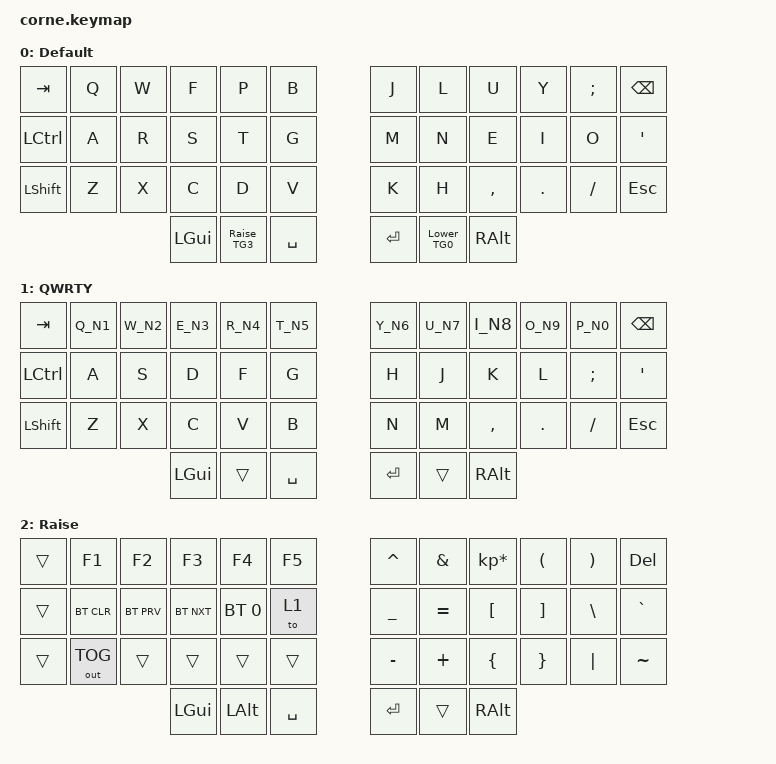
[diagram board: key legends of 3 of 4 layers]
/*
 * Copyright (c) 2020 The ZMK Contributors
 *
 * SPDX-License-Identifier: MIT
 */

#include <behaviors.dtsi>
#include <dt-bindings/zmk/bt.h>
#include <dt-bindings/zmk/keys.h>
#include <dt-bindings/zmk/outputs.h>

/ {
    behaviors {
        Lower_TG0: Lower_TG0 {
            compatible = "zmk,behavior-tap-dance";
            label = "LOWER_TG0";
            #binding-cells = <0>;
            bindings = <&mo 3>, <&tog 0>;

            tapping-term-ms = <200>;
        };

        Raise_TG3: Raise_TG3 {
            compatible = "zmk,behavior-tap-dance";
            label = "RAISE_TG3";
            #binding-cells = <0>;
            bindings = <&mo 2>, <&tog 1>;

            tapping-term-ms = <200>;
        };

        Q_N1: Q_N1 {
            compatible = "zmk,behavior-tap-dance";
            label = "Q_N1";
            #binding-cells = <0>;
            bindings = <&kp Q>, <&kp NUMBER_1>;

            tapping-term-ms = <200>;
        };

        W_N2: W_N2 {
            compatible = "zmk,behavior-tap-dance";
            label = "W_N2";
            #binding-cells = <0>;
            bindings = <&kp W>, <&kp NUMBER_2>;

            tapping-term-ms = <200>;
        };

        E_N3-8:

        E_N3-8 {
            compatible = "zmk,behavior-tap-dance";
            label = "E_N3-8";
            #binding-cells = <0>;
            bindings = <&kp E>, <&kp NUMBER_3>, <&kp N8>;

            tapping-term-ms = <175>;
        };

        F_N3: F_N3 {
            compatible = "zmk,behavior-tap-dance";
            label = "F_N3";
            #binding-cells = <0>;
            bindings = <&kp F>, <&kp NUMBER_3>;

            tapping-term-ms = <200>;
        };

        R_N4-9:

        R_N4-9 {
            compatible = "zmk,behavior-tap-dance";
            label = "R_N4-9";
            #binding-cells = <0>;
            bindings = <&kp R>, <&kp NUMBER_4>, <&kp N9>;

            tapping-term-ms = <175>;
        };

        P_N4: P_N4 {
            compatible = "zmk,behavior-tap-dance";
            label = "P_N4";
            #binding-cells = <0>;
            bindings = <&kp P>, <&kp NUMBER_4>;

            tapping-term-ms = <200>;
        };

        T_N5-0:

        T_N5-0 {
            compatible = "zmk,behavior-tap-dance";
            label = "T_N5-0";
            #binding-cells = <0>;
            bindings = <&kp T>, <&kp N5>, <&kp N0>;

            tapping-term-ms = <175>;
        };

        B_N5: B_N5 {
            compatible = "zmk,behavior-tap-dance";
            label = "B_N5";
            #binding-cells = <0>;
            bindings = <&kp B>, <&kp N5>;

            tapping-term-ms = <200>;
        };

        Y_N6: Y_N6 {
            compatible = "zmk,behavior-tap-dance";
            label = "Y_N6";
            #binding-cells = <0>;
            bindings = <&kp Y>, <&kp NUMBER_6>;

            tapping-term-ms = <200>;
        };

        J_N6: J_N6 {
            compatible = "zmk,behavior-tap-dance";
            label = "J_N6";
            #binding-cells = <0>;
            bindings = <&kp J>, <&kp NUMBER_6>;

            tapping-term-ms = <200>;
        };

        U_N7: U_N7 {
            compatible = "zmk,behavior-tap-dance";
            label = "U_N7";
            #binding-cells = <0>;
            bindings = <&kp U>, <&kp N7>;

            tapping-term-ms = <200>;
        };

        L_N7: L_N7 {
            compatible = "zmk,behavior-tap-dance";
            label = "L_N7";
            #binding-cells = <0>;
            bindings = <&kp L>, <&kp N7>;

            tapping-term-ms = <200>;
        };

        I_N8: I_N8 {
            compatible = "zmk,behavior-tap-dance";
            label = "I_N8";
            #binding-cells = <0>;
            bindings = <&kp I>, <&kp N8>;

            tapping-term-ms = <200>;
        };

        U_N8: U_N8 {
            compatible = "zmk,behavior-tap-dance";
            label = "U_N8";
            #binding-cells = <0>;
            bindings = <&kp U>, <&kp N8>;

            tapping-term-ms = <200>;
        };

        O_N9: O_N9 {
            compatible = "zmk,behavior-tap-dance";
            label = "O_N9";
            #binding-cells = <0>;
            bindings = <&kp O>, <&kp N9>;

            tapping-term-ms = <200>;
        };

        Y_N9: Y_N9 {
            compatible = "zmk,behavior-tap-dance";
            label = "Y_N9";
            #binding-cells = <0>;
            bindings = <&kp Y>, <&kp N9>;

            tapping-term-ms = <200>;
        };

        W_N2-7:

        W_N2-7 {
            compatible = "zmk,behavior-tap-dance";
            label = "W_N2-7";
            #binding-cells = <0>;
            bindings = <&kp W>, <&kp NUMBER_2>, <&kp N7>;

            tapping-term-ms = <175>;
        };

        CAP_CTRL: CAP_CTRL {
            compatible = "zmk,behavior-hold-tap";
            label = "CAP_CTRL";
            bindings = <&kp>, <&kp>;

            #binding-cells = <2>;
            tapping-term-ms = <200>;
            hold-trigger-key-positions = <12>;
        };

        Q_N1-6:

        Q_N1-6 {
            compatible = "zmk,behavior-tap-dance";
            label = "Q_N1-6";
            #binding-cells = <0>;
            bindings = <&kp Q>, <&kp NUMBER_1>, <&kp NUMBER_6>;

            tapping-term-ms = <175>;
        };

        W_N2-7:

        W_N2-7 { compatible = "zmk,behavior-tap-dance"; };

        Q_N1-6:

        Q_N1-6 { compatible = "zmk,behavior-tap-dance"; };
    };

    keymap {
        compatible = "zmk,keymap";

        default_layer {
            // -----------------------------------------------------------------------------------------
            // |  TAB |  Q  |  W  |  F  |  P  |  B  |   |  J  |  L   |  U  |  Y  |  :  | BKSP |
            // | CTRL |  A  |  R  |  S  |  T  |  G  |   |  M  |  J   |  K  |  I  |  O  |  '   |
            // | SHFT |  Z  |  X  |  C  |  D  |  V  |   |  K  |  H   |  ,  |  .  |  /  | ESC  |
            //                    | GUI | LWR | SPC |   | ENT | RSE  | ALT |

            bindings = <
&kp TAB    &kp Q  &kp W  &kp F     &kp P       &kp B        &kp J    &kp L       &kp U      &kp Y    &kp SEMI  &kp BSPC
&kp LCTRL  &kp A  &kp R  &kp S     &kp T       &kp G        &kp M    &kp N       &kp E      &kp I    &kp O     &kp SQT
&kp LSHFT  &kp Z  &kp X  &kp C     &kp D       &kp V        &kp K    &kp H       &kp COMMA  &kp DOT  &kp FSLH  &kp ESC
                         &kp LGUI  &Raise_TG3  &kp SPACE    &kp RET  &Lower_TG0  &kp RALT
            >;

            label = "Default";
        };

        QWRTY {
            bindings = <
&kp TAB    &Q_N1  &W_N2  &E_N3     &R_N4   &T_N5        &Y_N6      &U_N7   &I_N8          &O_N9    &P_N0     &kp BSPC
&kp LCTRL  &kp A  &kp S  &kp D     &kp F   &kp G        &kp H      &kp J   &kp K          &kp L    &kp SEMI  &kp APOS
&kp LSHFT  &kp Z  &kp X  &kp C     &kp V   &kp B        &kp N      &kp M   &kp COMMA      &kp DOT  &kp FSLH  &kp ESC
                         &kp LGUI  &trans  &kp SPACE    &kp ENTER  &trans  &kp RIGHT_ALT
            >;

            label = "QWRTY";
        };

        Raise {
            // -----------------------------------------------------------------------------------------
            // |  TAB |  !  |  @  |  #  |  $  |  %  |   |  ^  |  &  |  *  |  (  |  )  | BKSP |
            // | CTRL |     |     |     |     |     |   |  -  |  =  |  [  |  ]  |  \  |  `   |
            // | SHFT |     |     |     |     |     |   |  _  |  +  |  {  |  }  | "|" |  ~   |
            //                    | GUI |     | SPC |   | ENT |     | ALT |

            label = "Raise";
            bindings = <
&trans  &kp F1        &kp F2      &kp F3      &kp F4        &kp F5       &kp CARET  &kp AMPS   &kp KP_MULTIPLY  &kp LPAR  &kp RPAR  &kp DEL
&trans  &bt BT_CLR    &bt BT_PRV  &bt BT_NXT  &bt BT_SEL 0  &to 1        &kp UNDER  &kp EQUAL  &kp LBKT         &kp RBKT  &kp BSLH  &kp GRAVE
&trans  &out OUT_TOG  &trans      &trans      &trans        &trans       &kp MINUS  &kp PLUS   &kp LBRC         &kp RBRC  &kp PIPE  &kp TILDE
                                  &kp LGUI    &kp LEFT_ALT  &kp SPACE    &kp RET    &trans     &kp RALT
            >;
        };

        Lower {
            // -----------------------------------------------------------------------------------------
            // |  TAB |  1  |  2  |  3  |  4  |  5  |   |  6  |  7  |  8  |  9  |  0  | PG_UP |
            // | BTCLR| BT1 | BT2 | BT3 | BT4 | BT5 |   | LFT | DWN |  UP | RGT |     | PG_DN |
            // | SHFT | BT_NXT | BT_PRV |     |     |     |   |     |     |     |     |     |      |
            //                    | GUI |     | SPC |   | ENT |     | ALT |

            bindings = <
&kp TAB    &kp N1        &kp N2        &kp N3        &kp N4        &kp N5          &kp N6    &kp N7    &kp N8  &kp N9     &kp N0  &kp PG_UP
&trans     &bt BT_SEL 0  &bt BT_SEL 1  &bt BT_SEL 2  &bt BT_SEL 3  &bt BT_SEL 4    &kp LEFT  &kp DOWN  &kp UP  &kp RIGHT  &trans  &kp PG_DN
&kp LSHFT  &bt BT_NXT    &bt BT_PRV    &trans        &trans        &trans          &tog 0    &tog 1    &trans  &trans     &trans  &bt BT_CLR
                                       &kp LGUI      &trans        &kp SPACE       &kp RET   &trans
            >;

            label = "Lower";
        };
    };

    conditional_layers { compatible = "zmk,conditional-layers"; };
};

&nice_view_spi { cs-gpios = <&pro_micro 0 GPIO_ACTIVE_HIGH>; };
